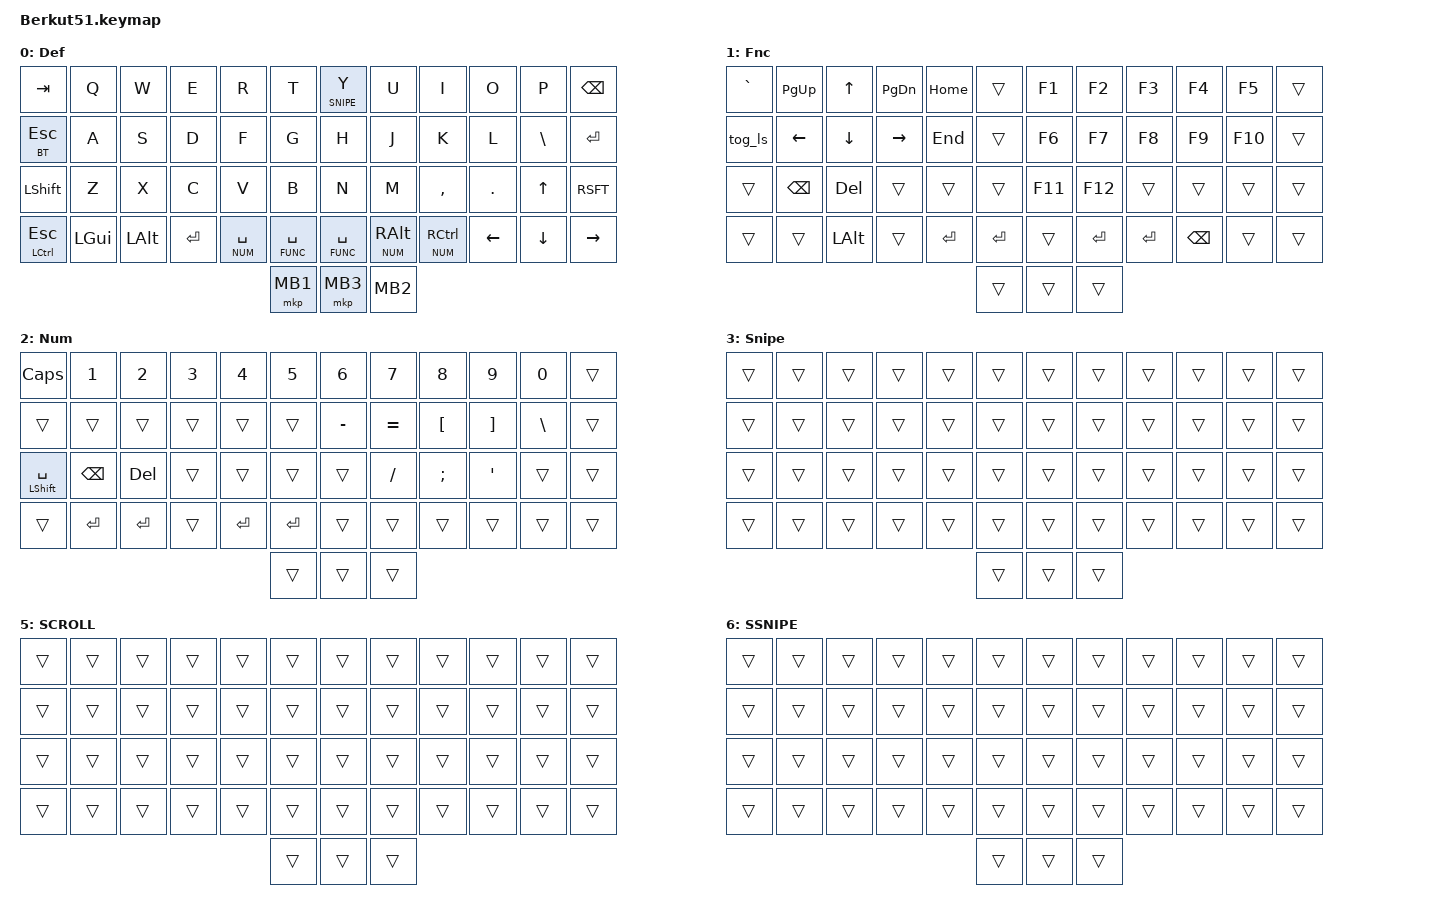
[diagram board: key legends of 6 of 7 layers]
// #include <layout_shift.dtsi>

#include <behaviors.dtsi>
#include <dt-bindings/zmk/bt.h>
#include <dt-bindings/zmk/keys.h>
#include <dt-bindings/zmk/pointing.h>
#include "layout_shift.dtsi"

/ {
    behaviors {
        // Keep the original key_press behavior for ZMK core components

        original_key_press: original_key_press {
            compatible = "zmk,behavior-key-press";
            #binding-cells = <1>;
            label = "KEY_PRESS";
        };

        // Override the existing &kp behavior to use our custom implementation

        kp: key_press {
            compatible = "zmk,behavior-layout-shift-key-press";
            #binding-cells = <1>;
            label = "LAYOUT_SHIFT_KEY_PRESS";
        };
    };
};

#define DEF 0
#define FUNC 1
#define NUM 2
#define SNIPE 3
#define BT 4
#define SCROLL 5
#define SSNIPE 6

/ {
    combos {
        compatible = "zmk,combos";

        COMBO_LANG1 {
            bindings = <&kp LANGUAGE_1>;
            key-positions = <1 2>;
        };

        COMBO_LANG2 {
            bindings = <&kp LANG2>;
            key-positions = <2 3>;
        };
    };

    keymap {
        compatible = "zmk,keymap";

        default_layer {
            label = "Def";
            bindings = <
&kp TAB       &kp Q     &kp W      &kp E     &kp R          &kp T                   &lt SNIPE Y     &kp U         &kp I         &kp O     &kp P     &kp BACKSPACE
&lt BT ESC    &kp A     &kp S      &kp D     &kp F          &kp G                   &kp H           &kp J         &kp K         &kp L     &kp BSLH  &kp ENTER
&kp LSHFT     &kp Z     &kp X      &kp C     &kp V          &kp B                   &kp N           &kp M         &kp COMMA     &kp DOT   &kp UP    &kp RSFT
&mt LCTL ESC  &kp LGUI  &kp LALT   &kp ENTER &lt NUM SPACE  &lt FUNC SPACE          &lt FUNC SPACE  &lt NUM RALT  &lt NUM RCTL  &kp LEFT  &kp DOWN  &kp RIGHT
                                                            &mkp MB1     &mkp MB3   &kp MB2
            >;
        };

        function_layer {
            label = "Fnc";
            bindings = <
&kp GRAVE  &kp PG_UP      &kp UP     &kp PG_DN  &kp HOME   &trans             &kp F1     &kp F2     &kp F3    &kp F4  &kp F5   &trans
&tog_ls    &kp LEFT       &kp DOWN   &kp RIGHT  &kp END    &trans             &kp F6     &kp F7     &kp F8    &kp F9  &kp F10  &trans
&trans     &kp BACKSPACE  &kp DEL    &trans     &trans     &trans             &kp F11    &kp F12    &trans    &trans  &trans &trans
&trans     &trans         &kp LALT    &trans        &kp ENTER  &kp ENTER    &trans       &kp ENTER  &kp ENTER  &kp BKSP  &trans  &trans   &trans
   &trans     &trans
            >;
        };

        num_layer {
            label = "Num";
            bindings = <
&kp CAPS         &kp N1         &kp N2     &kp N3    &kp N4     &kp N5             &kp N6     &kp N7     &kp N8    &kp N9    &kp N0    &trans
&trans           &trans         &trans     &trans    &trans     &trans             &kp MINUS  &kp EQUAL  &kp LBKT  &kp RBKT  &kp BSLH  &trans
&mt LSHFT SPACE  &kp BACKSPACE  &kp DEL    &trans    &trans     &trans             &trans     &kp FSLH   &kp SEMI  &kp SQT   &trans &trans
&trans           &kp ENTER      &kp ENTER  &trans   &kp ENTER  &kp ENTER    &trans      &trans     &trans     &trans    &trans    &trans    &trans
  &trans     &trans
            >;
        };

        snipe_layer {
            label = "Snipe";
            bindings = <
&trans    &trans  &trans     &trans    &trans     &trans          &trans  &trans  &trans  &trans  &trans  &trans
&trans    &trans  &trans     &trans    &trans     &trans          &trans  &trans  &trans  &trans  &trans  &trans
&trans    &trans  &trans     &trans    &trans     &trans          &trans  &trans  &trans  &trans  &trans &trans
&trans    &trans  &trans      &trans    &trans     &trans  &trans        &trans  &trans  &trans  &trans  &trans  &trans
 &trans  &trans
            >;
        };

        bt_layer {
            label = "BT";
            bindings = <
&bt BT_CLR  &bt BT_SEL 0  &bt BT_SEL 1  &bt BT_SEL 2  &bt BT_SEL 3  &bt BT_SEL 4          &bt BT_CLR_ALL  &trans  &trans  &trans  &trans  &trans
&trans      &trans        &trans        &trans        &trans        &trans                &trans          &trans  &trans  &trans  &trans  &trans
&trans      &trans        &trans        &trans        &trans        &trans                &trans          &trans  &trans  &trans  &trans
&trans      &trans        &trans                      &trans        &trans      &trans           &trans          &trans  &trans  &trans  &trans  &trans
        &trans  &trans
            >;
        };

        scroll_layer {
            label = "SCROLL";
            bindings = <
&trans      &trans        &trans        &trans        &trans        &trans                &trans          &trans  &trans  &trans  &trans  &trans
&trans      &trans        &trans        &trans        &trans        &trans                &trans          &trans  &trans  &trans  &trans  &trans
&trans      &trans        &trans        &trans        &trans        &trans                &trans          &trans  &trans  &trans  &trans &trans 
&trans      &trans        &trans          &trans      &trans        &trans     &trans         &trans          &trans  &trans  &trans  &trans  &trans
&trans     &trans
            >;
        };

        SSNIPE_layer {
            label = "SSNIPE";
            bindings = <
&trans      &trans        &trans        &trans        &trans        &trans                &trans          &trans  &trans  &trans  &trans  &trans
&trans      &trans        &trans        &trans        &trans        &trans                &trans          &trans  &trans  &trans  &trans  &trans
&trans      &trans        &trans        &trans        &trans        &trans                &trans          &trans  &trans  &trans  &trans &trans 
&trans      &trans        &trans          &trans      &trans        &trans     &trans         &trans          &trans  &trans  &trans  &trans  &trans
&trans     &trans
            >;
        };
    };
};
